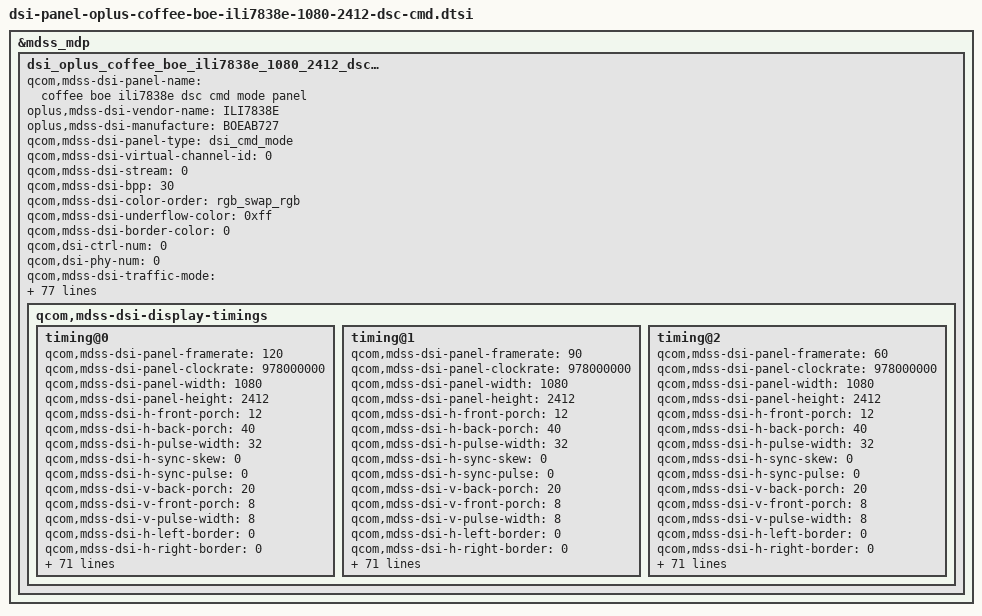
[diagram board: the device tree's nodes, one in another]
&mdss_mdp {
	dsi_oplus_coffee_boe_ili7838e_1080_2412_dsc_cmd: qcom,mdss_dsi_oplus_coffee_boe_ili7838e_1080_2412_dsc_cmd {
		qcom,mdss-dsi-panel-name = "coffee boe ili7838e dsc cmd mode panel";
		oplus,mdss-dsi-vendor-name = "ILI7838E";
		oplus,mdss-dsi-manufacture = "BOEAB727";
		qcom,mdss-dsi-panel-type = "dsi_cmd_mode";
		qcom,mdss-dsi-virtual-channel-id = <0>;
		qcom,mdss-dsi-stream = <0>;
		qcom,mdss-dsi-bpp = <30>;
		qcom,mdss-dsi-color-order = "rgb_swap_rgb";
		qcom,mdss-dsi-underflow-color = <0xff>;
		qcom,mdss-dsi-border-color = <0>;
		qcom,dsi-ctrl-num = <0>;
		qcom,dsi-phy-num = <0>;
		qcom,mdss-dsi-traffic-mode = "non_burst_sync_event";
		qcom,mdss-dsi-lane-map = "lane_map_0123";
		qcom,mdss-dsi-bllp-eof-power-mode;
		qcom,mdss-dsi-bllp-power-mode;
		qcom,mdss-dsi-lane-0-state;
		qcom,mdss-dsi-lane-1-state;
		qcom,mdss-dsi-lane-2-state;
		qcom,mdss-dsi-lane-3-state;
		qcom,mdss-dsi-dma-trigger = "trigger_sw";
		qcom,mdss-dsi-mdp-trigger = "none";
		qcom,mdss-dsi-reset-sequence = <1 5>, <0 5>, <1 20>;

		qcom,mdss-dsi-te-pin-select = <1>;
		qcom,mdss-dsi-te-dcs-command = <1>;
		qcom,mdss-dsi-te-check-enable;
		qcom,mdss-dsi-te-using-te-pin;
		qcom,mdss-dsi-lp11-init;
		qcom,mdss-dsi-wr-mem-start = <0x2c>;
		qcom,mdss-dsi-wr-mem-continue = <0x3c>;
		qcom,mdss-dsi-panel-hdr-enabled;
		qcom,mdss-dsi-panel-hdr-color-primaries = <15635 16450 34000 16000 13250 34500 7500 3000>;
		qcom,mdss-dsi-panel-peak-brightness = <5400000>;
		qcom,mdss-dsi-panel-blackness-level = <2000>;
		qcom,mdss-pan-physical-width-dimension = <70>;
		qcom,mdss-pan-physical-height-dimension = <155>;
		qcom,esd-check-enabled;
		qcom,mdss-dsi-panel-status-check-mode = "reg_read";
		qcom,mdss-dsi-panel-status-command = [
			06 01 00 01 05 00 01 0A
			06 01 00 01 05 00 01 B0
			06 01 00 01 05 00 01 B0
		];
		qcom,mdss-dsi-panel-status-command-state = "dsi_lp_mode";
		qcom,mdss-dsi-panel-status-value = <0x9C 0x05 0x0f>;
		qcom,mdss-dsi-panel-status-read-length = <1 1 1>;
		oplus,mdss-dsi-panel-status-match-modes = <0x06>;
		qcom,dynamic-mode-switch-enabled;
		qcom,dynamic-mode-switch-type = "dynamic-resolution-switch-immediate";
		qcom,mdss-dsi-display-timings {
			timing@0 {
				qcom,mdss-dsi-panel-framerate = <120>;
				qcom,mdss-dsi-panel-clockrate = <978000000>;
				qcom,mdss-dsi-panel-width = <1080>;
				qcom,mdss-dsi-panel-height = <2412>;
				qcom,mdss-dsi-h-front-porch = <12>;
				qcom,mdss-dsi-h-back-porch = <40>;
				qcom,mdss-dsi-h-pulse-width = <32>;
				qcom,mdss-dsi-h-sync-skew = <0>;
				qcom,mdss-dsi-h-sync-pulse = <0>;
				qcom,mdss-dsi-v-back-porch = <20>;
				qcom,mdss-dsi-v-front-porch = <8>;
				qcom,mdss-dsi-v-pulse-width = <8>;
				qcom,mdss-dsi-h-left-border = <0>;
				qcom,mdss-dsi-h-right-border = <0>;
				qcom,mdss-dsi-v-top-border = <0>;
				qcom,mdss-dsi-v-bottom-border = <0>;
				qcom,mdss-dsi-panel-jitter = <0x4 0x1>;

				oplus,fod-on-vblank = <0>;
				oplus,fod-off-vblank = <0>;
				qcom,mdss-dsi-timing-switch-command = [
					//120HZ
					39 00 00 40 00 00 04 FF 08 38 2D
					39 00 00 40 00 00 02 81 00
					39 00 00 00 00 00 04 FF 08 38 00
				];
				qcom,mdss-dsi-on-command = [
					39 01 00 00 00 00 04 FF 08 38 06
					39 01 00 00 00 00 02 C6 01
					39 01 00 00 00 00 04 FF 08 38 08
					39 01 00 00 00 00 02 D2 03
					39 01 00 00 00 00 04 FF 08 38 02
					39 01 00 00 00 00 02 F8 01
					39 01 00 00 00 00 04 FF 08 38 20
					39 01 00 00 00 00 02 B3 50
					39 01 00 00 00 00 02 B5 03
					39 01 00 00 00 00 04 FF 08 38 06
					39 01 00 00 00 00 02 D2 01
					39 01 00 00 00 00 02 A1 00

					/*add esd start*/
					39 01 00 00 00 00 04 FF 08 38 08
					39 01 00 00 00 00 02 D2 05
					39 01 00 00 00 00 04 FF 08 38 09
					39 01 00 00 00 00 0B 98 11 0F 10 0F 06 04 01 01 01 01
					/*add esd end*/

					39 01 00 00 00 00 04 FF 08 38 21
					39 01 00 00 00 00 02 A4 18
					39 01 00 00 00 00 04 FF 08 38 19
					39 01 00 00 00 00 02 C5 00
					39 01 00 00 00 00 04 FF 08 38 30
					39 01 00 00 00 00 02 87 04
					39 01 00 00 00 00 02 AE 01
					39 01 00 00 00 00 02 80 01
					/*R Corner Control off*/
					39 01 00 00 00 00 04 FF 08 38 17
					39 01 00 00 00 00 02 A0 3D
					39 01 00 00 00 00 04 FF 08 38 13
					39 01 00 00 00 00 02 F9 00

					39 01 00 00 00 00 04 FF 08 38 08
					39 01 00 00 00 00 02 C8 62

					//10bit DSC Setting
					39 01 00 00 00 00 04 FF 08 38 07
					39 01 00 00 00 00 02 8A 01
					39 01 00 00 00 00 03 8B 11 E0
					39 01 00 00 00 00 64 81 00 00 00
						00 00 12 00 00 AB 30 A0 09 6C 04
						38 00 0C 02 1C 02 A3 01 9A 01 D8
						00 19 01 03 00 0A 00 0C 08 BB 0A
						5F 16 00 10 EC 07 10 20 00 06 0F
						0F 33 0E 1C 2A 38 46 54 62 69 70
						77 79 7B 7D 7E 01 C2 22 00 2A 40
						32 BE 3A FC 3A FA 3A F8 3B 38 3B
						78 3B 76 4B B6 4B B6 4B F4 5B F4
						7C 34 34 00 00 00 00 00

					39 01 00 00 00 00 04 FF 08 38 2D
					39 01 00 00 00 00 02 81 00

					//IR IP off
					39 01 00 00 00 00 04 FF 08 38 00
					39 01 00 00 00 00 02 95 00

					39 01 00 00 00 00 02 35 00

					39 01 00 00 00 00 02 53 20
					39 01 00 00 00 00 03 51 0D BB
					05 01 00 00 79 00 01 11
					05 01 00 00 1F 00 01 29
					39 01 00 00 00 00 04 FF 08 38 20
				];
				qcom,mdss-dsi-off-command= [
					05 01 00 00 15 00 01 28
					05 01 00 00 79 00 01 10
					39 01 00 00 00 00 04 FF 08 38 06
					39 01 00 00 00 00 02 C5 55
				];
				qcom,mdss-dsi-post-on-backlight = [
					/* Display On */
					//39 00 00 40 00 00 04 FF 08 38 00
					//05 00 00 00 00 00 01 39
				];
				qcom,mdss-dsi-panel-info-switch-page-command = [
					/*read panel info switch page 1D*/
					39 00 00 00 00 00 04 FF 08 38 1D
				];
				qcom,mdss-dsi-default-switch-page-command = [
					/*switch default page*/
					39 00 00 00 00 00 04 FF 08 38 00
				];
				qcom,mdss-dsi-hbm-on-command = [
					//hbm
					39 00 00 40 00 00 04 FF 08 38 00
					39 00 00 00 00 00 05 51 0F FF 00 00
				];
				qcom,mdss-dsi-normal-hbm-on-command = [

				];
				qcom,mdss-dsi-hbm-off-command = [
					39 00 00 40 00 00 04 FF 08 38 00
					39 00 00 00 00 00 05 51 0D BB 00 00
				];
				qcom,mdss-dsi-aod-hbm-on-command = [

				];
				qcom,mdss-dsi-aod-hbm-off-command = [

				];
				qcom,mdss-dsi-aod-high-mode-command = [
					39 00 00 40 00 00 04 FF 08 38 00
					39 00 00 00 00 00 05 51 00 00 0D BB   //0F FE 75nits
				];
				qcom,mdss-dsi-aod-low-mode-command = [
					39 00 00 40 00 00 04 FF 08 38 00
					39 00 00 00 00 00 05 51 00 00 0A E0   //10nits  //0D BB 50nits
				];
				qcom,mdss-dsi-lp1-command = [
					/* AOD Switch */
					39 00 00 40 00 00 04 FF 08 38 00
					39 00 00 40 00 00 05 51 00 00 0D BB
					/* AOD Mode ON */
					39 00 00 40 00 00 04 FF 08 38 05
					15 00 00 40 00 00 02 80 19
					39 00 00 40 00 00 0A D0 FF AF 56 3D 2D 2D 2D 2D FF
					39 00 00 40 00 00 04 FF 08 38 00
					05 00 00 00 00 00 01 39
				];
				qcom,mdss-dsi-nolp-command = [
					//AOD OFF
					39 00 00 40 00 00 04 FF 08 38 00
					05 00 00 00 22 00 01 38
				];
				//qcom,mdss-dsi-seed-off-command = [

				//];
				//qcom,mdss-dsi-seed-3-command = [

				//];
				//qcom,mdss-dsi-seed-2-command = [

				//];
				//qcom,mdss-dsi-seed-1-command = [

				//];
				//qcom,mdss-dsi-seed-0-command = [

				//];
				qcom,mdss-dsi-hbm-enter-switch-command = [

				];
				qcom,mdss-dsi-hbm-exit-switch-command = [

				];
				qcom,mdss-dsi-osc-clk-mode0-command = [

				];
				qcom,mdss-dsi-osc-clk-mode1-command = [

				];
				qcom,mdss-dsi-esd-switch-page-command = [
					39 00 00 00 00 00 04 FF 08 38 20
				];
				qcom,mdss-dsi-timing-switch-command-state = "dsi_lp_mode";
				qcom,mdss-dsi-on-command-state = "dsi_lp_mode";
				qcom,mdss-dsi-off-command-state = "dsi_lp_mode";
				qcom,mdss-dsi-panel-info-switch-page-command-state = "dsi_lp_mode";
				qcom,mdss-dsi-default-switch-page-command-state = "dsi_lp_mode";
				qcom,mdss-dsi-hbm-on-command-state = "dsi_lp_mode";
				qcom,mdss-dsi-hbm-off-command-state = "dsi_lp_mode";
				qcom,mdss-dsi-lp1-command-state = "dsi_lp_mode";
				qcom,mdss-dsi-nolp-command-state = "dsi_lp_mode";
				qcom,mdss-dsi-aod-high-mode-command-state = "dsi_lp_mode";
				qcom,mdss-dsi-aod-low-mode-command-state = "dsi_lp_mode";
				qcom,mdss-dsi-osc-clk-mode0-command-state = "dsi_lp_mode";
				qcom,mdss-dsi-osc-clk-mode1-command-state = "dsi_lp_mode";
				//qcom,mdss-dsi-seed-0-command-state = "dsi_lp_mode";
				//qcom,mdss-dsi-seed-1-command-state = "dsi_lp_mode";
				//qcom,mdss-dsi-seed-2-command-state = "dsi_lp_mode";
				//qcom,mdss-dsi-seed-3-command-state = "dsi_lp_mode";
				//qcom,mdss-dsi-seed-off-command-state = "dsi_lp_mode";
				qcom,compression-mode = "dsc";
				qcom,mdss-dsc-slice-height = <12>;
				qcom,mdss-dsc-slice-width = <540>;
				qcom,mdss-dsc-slice-per-pkt = <2>;
				qcom,mdss-dsc-bit-per-component = <10>;
				qcom,mdss-dsc-bit-per-pixel = <10>;
				qcom,mdss-dsc-block-prediction-enable;
				qcom,mdss-dsc-version = <0x12>;
			};
			timing@1 {
				qcom,mdss-dsi-panel-framerate = <90>;
				qcom,mdss-dsi-panel-clockrate = <978000000>;
				qcom,mdss-dsi-panel-width = <1080>;
				qcom,mdss-dsi-panel-height = <2412>;
				qcom,mdss-dsi-h-front-porch = <12>;
				qcom,mdss-dsi-h-back-porch = <40>;
				qcom,mdss-dsi-h-pulse-width = <32>;
				qcom,mdss-dsi-h-sync-skew = <0>;
				qcom,mdss-dsi-h-sync-pulse = <0>;
				qcom,mdss-dsi-v-back-porch = <20>;
				qcom,mdss-dsi-v-front-porch = <8>;
				qcom,mdss-dsi-v-pulse-width = <8>;
				qcom,mdss-dsi-h-left-border = <0>;
				qcom,mdss-dsi-h-right-border = <0>;
				qcom,mdss-dsi-v-top-border = <0>;
				qcom,mdss-dsi-v-bottom-border = <0>;
				qcom,mdss-dsi-panel-jitter = <0x4 0x1>;

				oplus,fod-on-vblank = <0>;
				oplus,fod-off-vblank = <0>;
				qcom,mdss-dsi-timing-switch-command = [
					//90HZ
					39 00 00 40 00 00 04 FF 08 38 2D
					39 00 00 40 00 00 02 81 04
					39 00 00 00 00 00 04 FF 08 38 00
				];
				qcom,mdss-dsi-on-command = [
					39 01 00 00 00 00 04 FF 08 38 06
					39 01 00 00 00 00 02 C6 01
					39 01 00 00 00 00 04 FF 08 38 08
					39 01 00 00 00 00 02 D2 03
					39 01 00 00 00 00 04 FF 08 38 02
					39 01 00 00 00 00 02 F8 01
					39 01 00 00 00 00 04 FF 08 38 20
					39 01 00 00 00 00 02 B3 50
					39 01 00 00 00 00 02 B5 03
					39 01 00 00 00 00 04 FF 08 38 06
					39 01 00 00 00 00 02 D2 01
					39 01 00 00 00 00 02 A1 00

					/*add esd start*/
					39 01 00 00 00 00 04 FF 08 38 08
					39 01 00 00 00 00 02 D2 05
					39 01 00 00 00 00 04 FF 08 38 09
					39 01 00 00 00 00 0B 98 11 0F 10 0F 06 04 01 01 01 01
					/*add esd end*/

					39 01 00 00 00 00 04 FF 08 38 21
					39 01 00 00 00 00 02 A4 18
					39 01 00 00 00 00 04 FF 08 38 19
					39 01 00 00 00 00 02 C5 00
					39 01 00 00 00 00 04 FF 08 38 30
					39 01 00 00 00 00 02 87 04
					39 01 00 00 00 00 02 AE 01
					39 01 00 00 00 00 02 80 01
					/*R Corner Control off*/
					39 01 00 00 00 00 04 FF 08 38 17
					39 01 00 00 00 00 02 A0 3D
					39 01 00 00 00 00 04 FF 08 38 13
					39 01 00 00 00 00 02 F9 00

					39 01 00 00 00 00 04 FF 08 38 08
					39 01 00 00 00 00 02 C8 62

					//10bit DSC Setting
					39 01 00 00 00 00 04 FF 08 38 07
					39 01 00 00 00 00 02 8A 01
					39 01 00 00 00 00 03 8B 11 E0
					39 01 00 00 00 00 64 81 00 00 00
						00 00 12 00 00 AB 30 A0 09 6C 04
						38 00 0C 02 1C 02 A3 01 9A 01 D8
						00 19 01 03 00 0A 00 0C 08 BB 0A
						5F 16 00 10 EC 07 10 20 00 06 0F
						0F 33 0E 1C 2A 38 46 54 62 69 70
						77 79 7B 7D 7E 01 C2 22 00 2A 40
						32 BE 3A FC 3A FA 3A F8 3B 38 3B
						78 3B 76 4B B6 4B B6 4B F4 5B F4
						7C 34 34 00 00 00 00 00

					39 01 00 00 00 00 04 FF 08 38 2D
					39 01 00 00 00 00 02 81 04

					//IR IP off
					39 01 00 00 00 00 04 FF 08 38 00
					39 01 00 00 00 00 02 95 00

					39 01 00 00 00 00 02 35 00

					39 01 00 00 00 00 02 53 20
					39 01 00 00 00 00 03 51 0D BB
					05 01 00 00 79 00 01 11
					05 01 00 00 1F 00 01 29
					39 01 00 00 00 00 04 FF 08 38 20
				];
				qcom,mdss-dsi-off-command= [
					05 01 00 00 15 00 01 28
					05 01 00 00 79 00 01 10
					39 01 00 00 00 00 04 FF 08 38 06
					39 01 00 00 00 00 02 C5 55
				];
				qcom,mdss-dsi-post-on-backlight = [
					/* Display On */
					//39 00 00 40 00 00 04 FF 08 38 00
					//05 00 00 00 00 00 01 39
				];
				qcom,mdss-dsi-panel-info-switch-page-command = [
					/*read panel info switch page 1D*/
					39 00 00 00 00 00 04 FF 08 38 1D
				];
				qcom,mdss-dsi-default-switch-page-command = [
					/*switch default page*/
					39 00 00 00 00 00 04 FF 08 38 00
				];
				qcom,mdss-dsi-hbm-on-command = [
					//hbm
					39 00 00 40 00 00 04 FF 08 38 00
					39 00 00 40 00 00 05 51 0F FF 00 00
					39 00 00 00 00 00 04 FF 08 38 20
				];
				qcom,mdss-dsi-normal-hbm-on-command = [

				];
				qcom,mdss-dsi-hbm-off-command = [
					39 00 00 40 00 00 04 FF 08 38 00
					39 00 00 40 00 00 05 51 0D BB 00 00
					39 00 00 00 00 00 04 FF 08 38 20
				];
				qcom,mdss-dsi-aod-hbm-on-command = [

				];
				qcom,mdss-dsi-aod-hbm-off-command = [

				];
				qcom,mdss-dsi-aod-high-mode-command = [
					39 00 00 40 00 00 04 FF 08 38 00
					39 00 00 00 00 00 05 51 00 00 0D BB   //0F FE 75nits
				];
				qcom,mdss-dsi-aod-low-mode-command = [
					39 00 00 40 00 00 04 FF 08 38 00
					39 00 00 00 00 00 05 51 00 00 0A E0   //10nits  //0D BB 50nits
				];
				qcom,mdss-dsi-lp1-command = [
					/* AOD Switch */
					39 00 00 40 00 00 04 FF 08 38 00
					39 00 00 40 00 00 05 51 00 00 0D BB
					/* AOD Mode ON */
					39 00 00 40 00 00 04 FF 08 38 05
					15 00 00 40 00 00 02 80 19
					39 00 00 40 00 00 0A D0 FF AF 56 3D 2D 2D 2D 2D FF
					39 00 00 40 00 00 04 FF 08 38 00
					05 00 00 00 00 00 01 39
				];
				qcom,mdss-dsi-nolp-command = [
					//AOD OFF
					39 00 00 40 00 00 04 FF 08 38 00
					05 00 00 00 22 00 01 38
				];
				qcom,mdss-dsi-hbm-enter-switch-command = [

				];
				qcom,mdss-dsi-hbm-exit-switch-command = [

				];
				qcom,mdss-dsi-osc-clk-mode0-command = [

				];
				qcom,mdss-dsi-osc-clk-mode1-command = [

				];
				qcom,mdss-dsi-esd-switch-page-command = [
					39 00 00 40 00 00 04 FF 08 38 20
				];
				qcom,mdss-dsi-timing-switch-command-state = "dsi_lp_mode";
				qcom,mdss-dsi-on-command-state = "dsi_lp_mode";
				qcom,mdss-dsi-off-command-state = "dsi_lp_mode";
				qcom,mdss-dsi-panel-info-switch-page-command-state = "dsi_lp_mode";
				qcom,mdss-dsi-default-switch-page-command-state = "dsi_lp_mode";
				qcom,mdss-dsi-hbm-on-command-state = "dsi_lp_mode";
				qcom,mdss-dsi-hbm-off-command-state = "dsi_lp_mode";
				qcom,mdss-dsi-lp1-command-state = "dsi_lp_mode";
				qcom,mdss-dsi-nolp-command-state = "dsi_lp_mode";
				qcom,mdss-dsi-aod-high-mode-command-state = "dsi_lp_mode";
				qcom,mdss-dsi-aod-low-mode-command-state = "dsi_lp_mode";
				qcom,mdss-dsi-osc-clk-mode0-command-state = "dsi_lp_mode";
				qcom,mdss-dsi-osc-clk-mode1-command-state = "dsi_lp_mode";
				qcom,compression-mode = "dsc";
				qcom,mdss-dsc-slice-height = <12>;
				qcom,mdss-dsc-slice-width = <540>;
				qcom,mdss-dsc-slice-per-pkt = <2>;
				qcom,mdss-dsc-bit-per-component = <10>;
				qcom,mdss-dsc-bit-per-pixel = <10>;
				qcom,mdss-dsc-block-prediction-enable;
				qcom,mdss-dsc-version = <0x12>;
			};
			timing@2 {
				qcom,mdss-dsi-panel-framerate = <60>;
				qcom,mdss-dsi-panel-clockrate = <978000000>;
				qcom,mdss-dsi-panel-width = <1080>;
				qcom,mdss-dsi-panel-height = <2412>;
				qcom,mdss-dsi-h-front-porch = <12>;
				qcom,mdss-dsi-h-back-porch = <40>;
				qcom,mdss-dsi-h-pulse-width = <32>;
				qcom,mdss-dsi-h-sync-skew = <0>;
				qcom,mdss-dsi-h-sync-pulse = <0>;
				qcom,mdss-dsi-v-back-porch = <20>;
				qcom,mdss-dsi-v-front-porch = <8>;
				qcom,mdss-dsi-v-pulse-width = <8>;
				qcom,mdss-dsi-h-left-border = <0>;
				qcom,mdss-dsi-h-right-border = <0>;
				qcom,mdss-dsi-v-top-border = <0>;
				qcom,mdss-dsi-v-bottom-border = <0>;
				qcom,mdss-dsi-panel-jitter = <0x4 0x1>;

				oplus,fod-on-vblank = <0>;
				oplus,fod-off-vblank = <0>;
				qcom,mdss-dsi-timing-switch-command = [
					//60HZ
					39 00 00 40 00 00 04 FF 08 38 2D
					39 00 00 40 00 00 02 81 05
					39 00 00 00 00 00 04 FF 08 38 00
				];
				qcom,mdss-dsi-on-command = [
					39 01 00 00 00 00 04 FF 08 38 06
					39 01 00 00 00 00 02 C6 01
					39 01 00 00 00 00 04 FF 08 38 08
					39 01 00 00 00 00 02 D2 03
					39 01 00 00 00 00 04 FF 08 38 02
					39 01 00 00 00 00 02 F8 01
					39 01 00 00 00 00 04 FF 08 38 20
					39 01 00 00 00 00 02 B3 50
					39 01 00 00 00 00 02 B5 03
					39 01 00 00 00 00 04 FF 08 38 06
					39 01 00 00 00 00 02 D2 01
					39 01 00 00 00 00 02 A1 00
					/*add esd start*/
					39 01 00 00 00 00 04 FF 08 38 08
					39 01 00 00 00 00 02 D2 05
					39 01 00 00 00 00 04 FF 08 38 09
					39 01 00 00 00 00 0B 98 11 0F 10 0F 06 04 01 01 01 01
					/*add esd end*/
					39 01 00 00 00 00 04 FF 08 38 21
					39 01 00 00 00 00 02 A4 18
					39 01 00 00 00 00 04 FF 08 38 19
					39 01 00 00 00 00 02 C5 00
					39 01 00 00 00 00 04 FF 08 38 30
					39 01 00 00 00 00 02 87 04
					39 01 00 00 00 00 02 AE 01
					39 01 00 00 00 00 02 80 01
					/*R Corner Control off*/
					39 01 00 00 00 00 04 FF 08 38 17
					39 01 00 00 00 00 02 A0 3D
					39 01 00 00 00 00 04 FF 08 38 13
					39 01 00 00 00 00 02 F9 00

					39 01 00 00 00 00 04 FF 08 38 08
					39 01 00 00 00 00 02 C8 62

					//10bit DSC Setting
					39 01 00 00 00 00 04 FF 08 38 07
					39 01 00 00 00 00 02 8A 01
					39 01 00 00 00 00 03 8B 11 E0
					39 01 00 00 00 00 64 81 00 00 00
						00 00 12 00 00 AB 30 A0 09 6C 04
						38 00 0C 02 1C 02 A3 01 9A 01 D8
						00 19 01 03 00 0A 00 0C 08 BB 0A
						5F 16 00 10 EC 07 10 20 00 06 0F
						0F 33 0E 1C 2A 38 46 54 62 69 70
						77 79 7B 7D 7E 01 C2 22 00 2A 40
						32 BE 3A FC 3A FA 3A F8 3B 38 3B
						78 3B 76 4B B6 4B B6 4B F4 5B F4
						7C 34 00 00 00 00 00 00

					39 01 00 00 00 00 04 FF 08 38 2D
					39 01 00 00 00 00 02 81 05

					//IR IP off
					39 01 00 00 00 00 04 FF 08 38 00
					39 01 00 00 00 00 02 95 00

					39 01 00 00 00 00 02 35 00

					39 01 00 00 00 00 02 53 20
					39 01 00 00 00 00 03 51 0D BB
					05 01 00 00 79 00 01 11
					05 01 00 00 1F 00 01 29
					39 01 00 00 00 00 04 FF 08 38 20
				];
				qcom,mdss-dsi-off-command= [
					05 01 00 00 15 00 01 28
					05 01 00 00 79 00 01 10
					39 01 00 00 00 00 04 FF 08 38 06
					39 01 00 00 00 00 02 C5 55
				];
				qcom,mdss-dsi-post-on-backlight = [
					/* Display On */
					//39 00 00 40 00 00 04 FF 08 38 00
					//05 00 00 00 00 00 01 39
				];
				qcom,mdss-dsi-panel-info-switch-page-command = [
					/*read panel info switch page 1D*/
					39 00 00 00 00 00 04 FF 08 38 1D
				];
				qcom,mdss-dsi-default-switch-page-command = [
					/*switch default page*/
					39 00 00 00 00 00 04 FF 08 38 00
				];
				qcom,mdss-dsi-hbm-on-command = [
					//hbm
					39 00 00 40 00 00 04 FF 08 38 00
					39 00 00 40 00 00 05 51 0F FF 00 00
					39 00 00 00 00 00 04 FF 08 38 20
				];
				qcom,mdss-dsi-normal-hbm-on-command = [

				];
				qcom,mdss-dsi-hbm-off-command = [
					39 00 00 40 00 00 04 FF 08 38 00
					39 00 00 40 00 00 05 51 0D BB 00 00
					39 00 00 00 00 00 04 FF 08 38 20
				];
				qcom,mdss-dsi-aod-hbm-on-command = [

				];
				qcom,mdss-dsi-aod-hbm-off-command = [

				];
				qcom,mdss-dsi-aod-high-mode-command = [
					39 00 00 40 00 00 04 FF 08 38 00
					39 00 00 00 00 00 05 51 00 00 0D BB   //0F FE 75nits
				];
				qcom,mdss-dsi-aod-low-mode-command = [
					39 00 00 40 00 00 04 FF 08 38 00
					39 00 00 00 00 00 05 51 00 00 0A E0   //10nits  //0D BB 50nits
				];
				qcom,mdss-dsi-lp1-command = [
					/* AOD Switch */
					39 00 00 40 00 00 04 FF 08 38 00
					39 00 00 40 00 00 05 51 00 00 0D BB
					/* AOD Mode ON */
					39 00 00 40 00 00 04 FF 08 38 05
					15 00 00 40 00 00 02 80 19
					39 00 00 40 00 00 0A D0 FF AF 56 3D 2D 2D 2D 2D FF
					39 00 00 40 00 00 04 FF 08 38 00
					05 00 00 00 00 00 01 39
				];
				qcom,mdss-dsi-nolp-command = [
					//AOD OFF
					39 00 00 40 00 00 04 FF 08 38 00
					05 00 00 00 22 00 01 38
				];
				//qcom,mdss-dsi-seed-off-command = [

				//];
				//qcom,mdss-dsi-seed-3-command = [

				//];
				//qcom,mdss-dsi-seed-2-command = [

				//];
				//qcom,mdss-dsi-seed-1-command = [

				//];
				//qcom,mdss-dsi-seed-0-command = [

				//];
				qcom,mdss-dsi-hbm-enter-switch-command = [

				];
				qcom,mdss-dsi-hbm-exit-switch-command = [

				];
				qcom,mdss-dsi-osc-clk-mode0-command = [

				];
				qcom,mdss-dsi-osc-clk-mode1-command = [

				];
				qcom,mdss-dsi-esd-switch-page-command = [
					39 00 00 00 00 00 04 FF 08 38 20
				];
				qcom,mdss-dsi-timing-switch-command-state = "dsi_lp_mode";
				qcom,mdss-dsi-on-command-state = "dsi_lp_mode";
				qcom,mdss-dsi-off-command-state = "dsi_lp_mode";
				qcom,mdss-dsi-panel-info-switch-page-command-state = "dsi_lp_mode";
				qcom,mdss-dsi-default-switch-page-command-state = "dsi_lp_mode";
				qcom,mdss-dsi-hbm-on-command-state = "dsi_lp_mode";
				qcom,mdss-dsi-hbm-off-command-state = "dsi_lp_mode";
				qcom,mdss-dsi-lp1-command-state = "dsi_lp_mode";
				qcom,mdss-dsi-nolp-command-state = "dsi_lp_mode";
				qcom,mdss-dsi-aod-high-mode-command-state = "dsi_lp_mode";
				qcom,mdss-dsi-aod-low-mode-command-state = "dsi_lp_mode";
				qcom,mdss-dsi-osc-clk-mode0-command-state = "dsi_lp_mode";
				qcom,mdss-dsi-osc-clk-mode1-command-state = "dsi_lp_mode";
				//qcom,mdss-dsi-seed-0-command-state = "dsi_lp_mode";
				//qcom,mdss-dsi-seed-1-command-state = "dsi_lp_mode";
				//qcom,mdss-dsi-seed-2-command-state = "dsi_lp_mode";
				//qcom,mdss-dsi-seed-3-command-state = "dsi_lp_mode";
				//qcom,mdss-dsi-seed-off-command-state = "dsi_lp_mode";
				qcom,compression-mode = "dsc";
				qcom,mdss-dsc-slice-height = <12>;
				qcom,mdss-dsc-slice-width = <540>;
				qcom,mdss-dsc-slice-per-pkt = <2>;
				qcom,mdss-dsc-bit-per-component = <10>;
				qcom,mdss-dsc-bit-per-pixel = <10>;
				qcom,mdss-dsc-block-prediction-enable;
				qcom,mdss-dsc-version = <0x12>;
			};
		};
	};
};



&dsi_oplus_coffee_boe_ili7838e_1080_2412_dsc_cmd {
	qcom,panel-supply-entries = <&dsi_panel_oplus_pwr_supply_coffee>;
	qcom,mdss-dsi-panel-controller = <&mdss_dsi0>;
	qcom,mdss-dsi-bl-pmic-control-type = "bl_ctrl_dcs";
	qcom,mdss-dsi-bl-inverted-dbv;
	qcom,mdss-dsi-bl-min-level = <1>;
	qcom,mdss-dsi-bl-max-level = <4095>;
	qcom,mdss-brightness-max-level = <4095>;
	oplus,dsi-bl-normal-max-level = <3515>;
	oplus,dsi-brightness-normal-max-level = <3515>;
	oplus,dsi-brightness-default-level = <2047>;
	/* ofp config */
	oplus,ofp-fp-type = <0x08>;
	oplus,ofp-need-to-wait-data-before-aod-on;
	qcom,platform-te-gpio = <&tlmm 99 0>;
	qcom,platform-reset-gpio = <&tlmm 98 0>;
	qcom,platform-reset-gpio-always-on;
	qcom,ulps-enabled;
	qcom,dsi-select-clocks = "pll_byte_clk0", "pll_dsi_clk0";
	/* serial num config */
	oplus,dsi-serial-number-enabled;
	oplus,dsi-serial-number-switch-page;
	oplus,dsi-serial-number-index= <0>;
	oplus,dsi-serial-number-reg= <0x81>;
	oplus,dsi-serial-number-read-count= <17>;
	oplus,dsi-fod-brightness = <36 0xed>,
			<60 0xec>,
			<90 0xeb>,
			<140 0xea>,
			<200 0xe8>,
			<300 0xe4>,
			<458 0xe0>,
			<605 0xdb>,
			<743 0xcf>,
			<912 0xc8>,
			<1062 0xbf>,
			<1187 0xb6>,
			<1393 0xa0>,
			<1611 0x9b>,
			<1787 0x92>,
			<2000 0x8b>,
			<2200 0x80>,
			<2400 0x70>,
			<2600 0x60>,
			<2800 0x50>,
			<3000 0x4A>,
			<3200 0x40>,
			<3400 0x36>,
			<3515 0x2e>;

	qcom,mdss-dsi-display-timings {
		timing@0 {
				qcom,mdss-dsi-panel-phy-timings = [00 21 08 08 19 16 09 08 09 02 04 00 1C 0D];
				qcom,display-topology = <1 1 1>;
				qcom,default-topology-index = <0>;
		};
		timing@1 {
				qcom,mdss-dsi-panel-phy-timings = [00 21 08 08 19 16 09 08 09 02 04 00 1C 0D];
				qcom,display-topology = <1 1 1>;
				qcom,default-topology-index = <0>;
		};
		timing@2 {
				qcom,mdss-dsi-panel-phy-timings = [00 21 08 08 19 16 09 08 09 02 04 00 1C 0D];
				qcom,display-topology = <1 1 1>;
				qcom,default-topology-index = <0>;
		};
	};
};

&dsi_oplus_coffee_boe_ili7838e_1080_2412_dsc_cmd {
	qcom,panel_voltage_vddi_name = "vddio";
	qcom,panel_voltage_vddi = <0 1800000 1850000 1950000>;
	qcom,panel_voltage_vddr_name = "vddio";
	qcom,panel_voltage_vddr = <1 1800000 1850000 1950000>;
};
